# STM32WB55x register map
File version: 1.0
CPU: CM4 r0p1, little endian, 4 interrupt priority bits
Registers are 32-bit, read-write, reset 0x0 unless marked. A register's access mark holds for its fields unless they carry their own. Offsets are from the block's base; [hi:lo] are bit positions; {n}, {i} and the like mark numbered series; 'fields as' and 'values as' point back to an identical list.

## SAI
Base 0x40015400
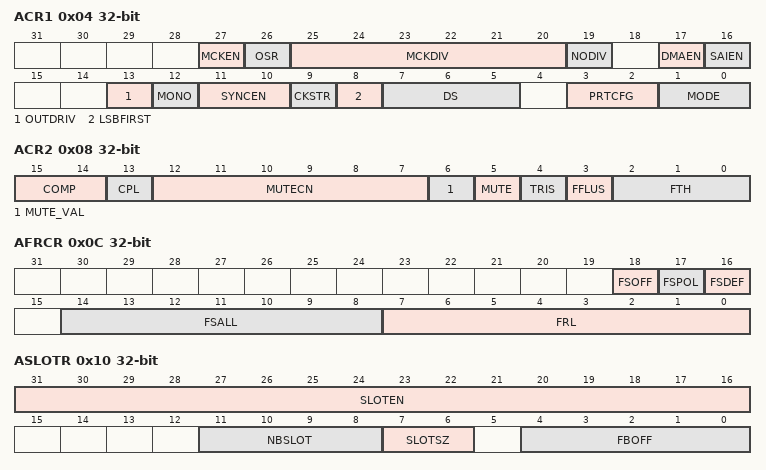
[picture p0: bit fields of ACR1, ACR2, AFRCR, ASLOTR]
0x04 ACR1
  [27] MCKEN, [26] OSR, [25:20] MCKDIV, [19] NODIV, [17] DMAEN, [16] SAIEN, [13] OUTDRIV, [12] MONO, [11:10] SYNCEN, [9] CKSTR, [8] LSBFIRST, [7:5] DS, [3:2] PRTCFG, [1:0] MODE
0x08 ACR2
  [15:14] COMP, [13] CPL, [12:7] MUTECN, [6] MUTE_VAL, [5] MUTE, [4] TRIS, [3] FFLUS, [2:0] FTH
0x0C AFRCR
  [18] FSOFF, [17] FSPOL, [16] FSDEF, [14:8] FSALL, [7:0] FRL
0x10 ASLOTR
  [31:16] SLOTEN, [11:8] NBSLOT, [7:6] SLOTSZ, [4:0] FBOFF
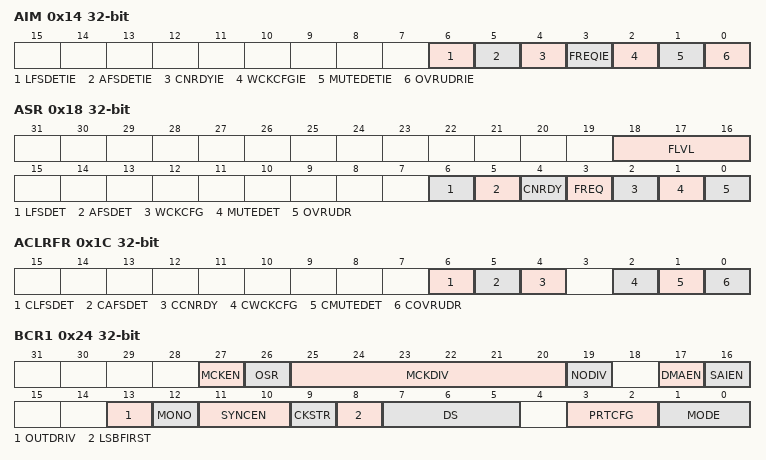
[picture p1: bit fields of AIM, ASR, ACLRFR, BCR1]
0x14 AIM
  [6] LFSDETIE, [5] AFSDETIE, [4] CNRDYIE, [3] FREQIE, [2] WCKCFGIE, [1] MUTEDETIE, [0] OVRUDRIE
0x18 ASR
  [18:16] FLVL, [6] LFSDET, [5] AFSDET, [4] CNRDY, [3] FREQ, [2] WCKCFG, [1] MUTEDET, [0] OVRUDR
0x1C ACLRFR
  [6] CLFSDET, [5] CAFSDET, [4] CCNRDY, [2] CWCKCFG, [1] CMUTEDET, [0] COVRUDR
0x20 ADR
  [31:0] DATA
0x24 BCR1
  fields as ACR1
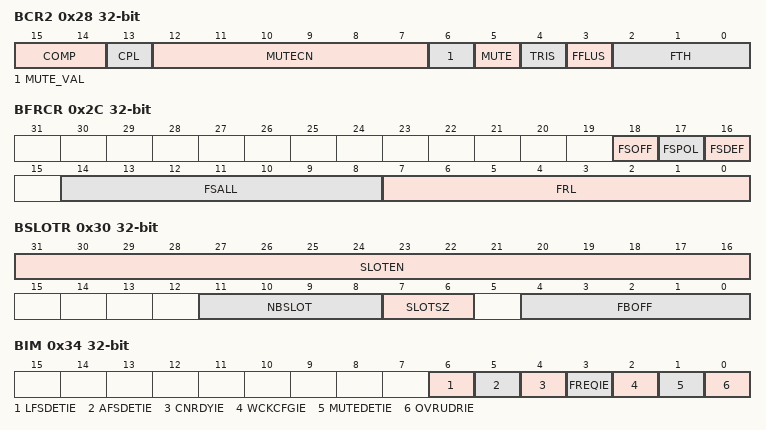
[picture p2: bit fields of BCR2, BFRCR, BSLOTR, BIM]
0x28 BCR2
  fields as ACR2
0x2C BFRCR
  [18] FSOFF, [17] FSPOL, [16] FSDEF, [14:8] FSALL, [7:0] FRL
0x30 BSLOTR
  [31:16] SLOTEN, [11:8] NBSLOT, [7:6] SLOTSZ, [4:0] FBOFF
0x34 BIM
  fields as AIM
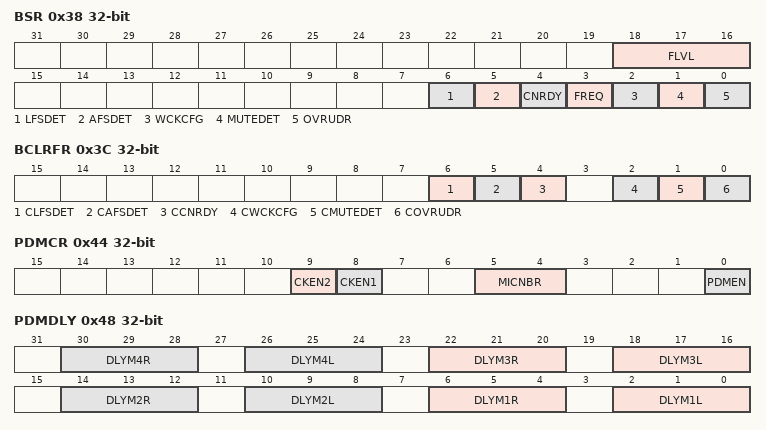
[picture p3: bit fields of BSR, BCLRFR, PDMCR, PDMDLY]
0x38 BSR
  fields as ASR
0x3C BCLRFR
  fields as ACLRFR
0x40 BDR
  [31:0] DATA
0x44 PDMCR
  [9] CKEN2, [8] CKEN1, [5:4] MICNBR, [0] PDMEN
0x48 PDMDLY
  [8n-2:8n-4] DLYM{n}R (n=1..4), [8n-6:8n-8] DLYM{n}L (n=1..4)

## QUADSPI
Base 0xA0001000
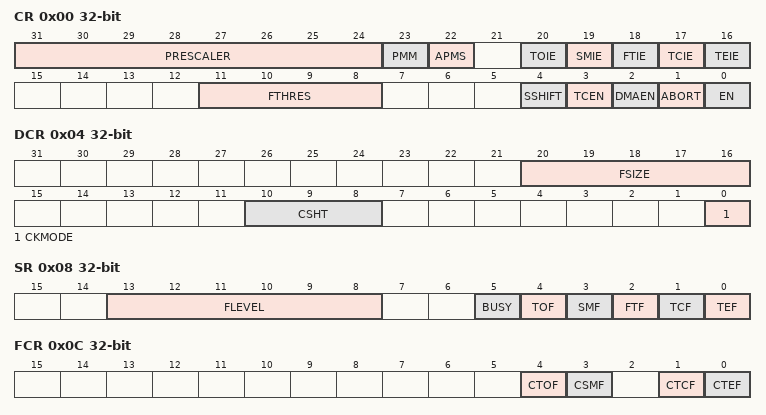
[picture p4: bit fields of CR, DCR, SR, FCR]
0x00 CR
  [31:24] PRESCALER, [23] PMM, [22] APMS, [20] TOIE, [19] SMIE, [18] FTIE, [17] TCIE, [16] TEIE, [11:8] FTHRES, [4] SSHIFT, [3] TCEN, [2] DMAEN, [1] ABORT, [0] EN
0x04 DCR
  [20:16] FSIZE, [10:8] CSHT, [0] CKMODE
0x08 SR
  [13:8] FLEVEL, [5] BUSY, [4] TOF, [3] SMF, [2] FTF, [1] TCF, [0] TEF
0x0C FCR
  [4] CTOF, [3] CSMF, [1] CTCF, [0] CTEF
0x10 DLR
  [31:0] DL
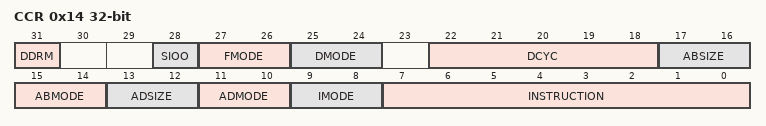
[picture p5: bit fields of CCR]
0x14 CCR
  [31] DDRM, [28] SIOO, [27:26] FMODE, [25:24] DMODE, [22:18] DCYC, [17:16] ABSIZE, [15:14] ABMODE, [13:12] ADSIZE, [11:10] ADMODE, [9:8] IMODE, [7:0] INSTRUCTION
0x18 AR
  [31:0] ADDRESS
0x1C ABR
  [31:0] ALTERNATE
0x20 DR
  [31:0] DATA
0x24 PSMKR
  [31:0] MASK
0x28 PSMAR
  [31:0] MATCH
0x2C PIR
  [15:0] INTERVAL
0x30 LPTR
  [15:0] TIMEOUT

## SYSCFG
Base 0x40010000
0x00 MEMRMP
  [2:0] MEM_MODE
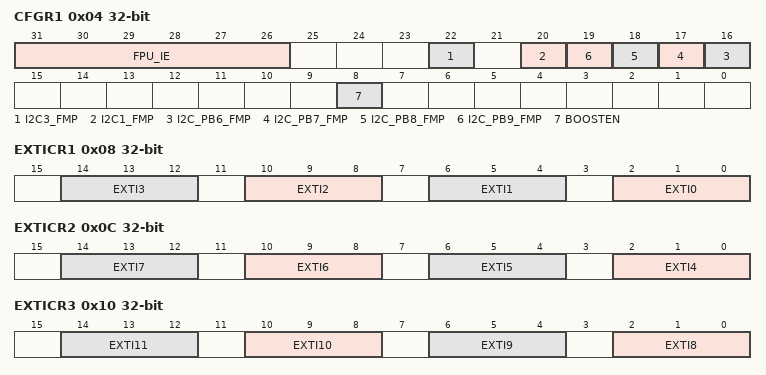
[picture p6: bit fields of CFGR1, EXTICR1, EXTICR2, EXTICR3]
0x04 CFGR1
  [31:26] FPU_IE, [22] I2C3_FMP, [20] I2C1_FMP, [n+10] I2C_PB{n}_FMP (n=6..9), [8] BOOSTEN
0x08 EXTICR1
  [4n+2:4n] EXTI{n} (n=0..3)
0x0C EXTICR2
  [4n-14:4n-16] EXTI{n} (n=4..7)
0x10 EXTICR3
  [4n-30:4n-32] EXTI{n} (n=8..11)
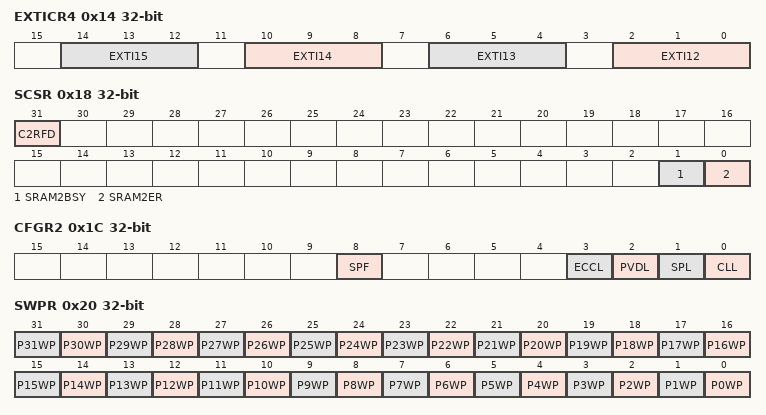
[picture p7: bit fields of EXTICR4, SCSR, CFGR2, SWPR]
0x14 EXTICR4
  [4n-46:4n-48] EXTI{n} (n=12..15)
0x18 SCSR
  [31] C2RFD, [1] SRAM2BSY, [0] SRAM2ER
0x1C CFGR2
  [8] SPF, [3] ECCL, [2] PVDL, [1] SPL, [0] CLL
0x20 SWPR
  [n] P{n}WP (n=0..31)
0x24 SKR
  [7:0] KEY
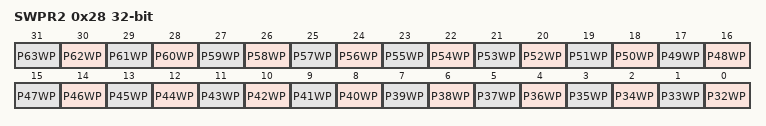
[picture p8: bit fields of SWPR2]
0x28 SWPR2
  [n-32] P{n}WP (n=32..63)

## SYSCFG2
Base 0x40010000
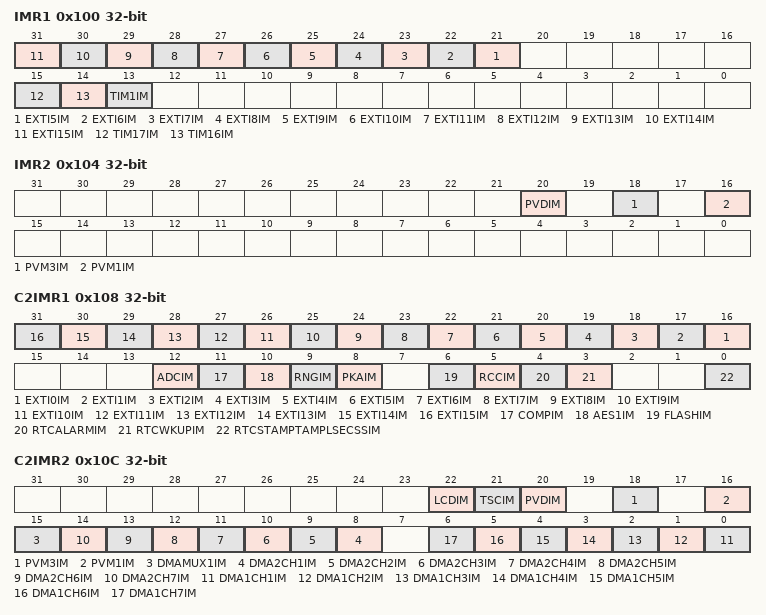
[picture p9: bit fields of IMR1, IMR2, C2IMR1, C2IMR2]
0x100 IMR1
  [n+16] EXTI{n}IM (n=5..15), [15] TIM17IM, [14] TIM16IM, [13] TIM1IM
0x104 IMR2
  [20] PVDIM, [18] PVM3IM, [16] PVM1IM
0x108 C2IMR1
  [n+16] EXTI{n}IM (n=0..15), [12] ADCIM, [11] COMPIM, [10] AES1IM, [9] RNGIM, [8] PKAIM, [6] FLASHIM, [5] RCCIM, [4] RTCALARMIM, [3] RTCWKUPIM, [0] RTCSTAMPTAMPLSECSSIM
0x10C C2IMR2
  [22] LCDIM, [21] TSCIM, [20] PVDIM, [18] PVM3IM, [16] PVM1IM, [15] DMAMUX1IM, [n+7] DMA2CH{n}IM (n=1..7), [n-1] DMA1CH{n}IM (n=1..7)
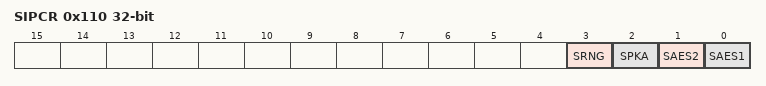
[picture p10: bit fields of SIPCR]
0x110 SIPCR
  [3] SRNG, [2] SPKA, [1] SAES2, [0] SAES1

## VREFBUF
Base 0x40010030
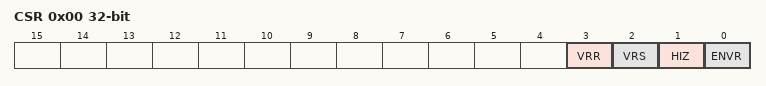
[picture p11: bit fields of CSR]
0x00 CSR
  [3] VRR, [2] VRS, [1] HIZ, [0] ENVR
0x04 CCR
  [5:0] TRIM

## IPCC
Base 0x58000C00
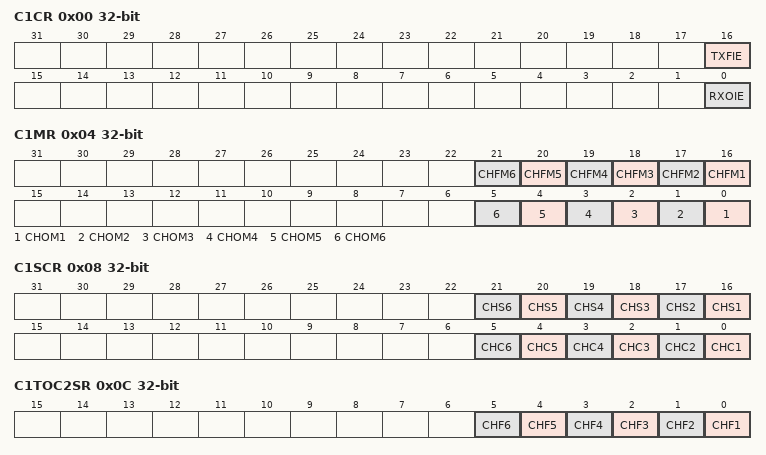
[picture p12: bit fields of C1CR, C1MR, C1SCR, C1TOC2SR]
0x00 C1CR
  [16] TXFIE, [0] RXOIE
0x04 C1MR
  [n+15] CHFM{n} (n=1..6), [n-1] CHOM{n} (n=1..6)
0x08 C1SCR
  [n+15] CHS{n} (n=1..6), [n-1] CHC{n} (n=1..6)
0x0C C1TOC2SR
  [n-1] CHF{n} (n=1..6)
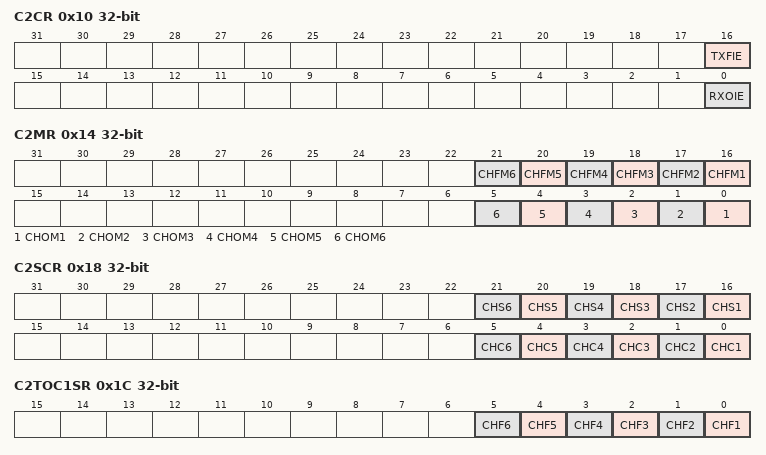
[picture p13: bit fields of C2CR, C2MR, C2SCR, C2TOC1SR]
0x10 C2CR
  [16] TXFIE, [0] RXOIE
0x14 C2MR
  [n+15] CHFM{n} (n=1..6), [n-1] CHOM{n} (n=1..6)
0x18 C2SCR
  [n+15] CHS{n} (n=1..6), [n-1] CHC{n} (n=1..6)
0x1C C2TOC1SR
  [n-1] CHF{n} (n=1..6)
